# BL702 register map
Vendor: Bouffalo Lab; Series: WiFi BT; File version: 1.0
BL702 BLE + Zigbee combo chipset
Registers are 32-bit, read-write, reset 0x0 unless marked. A register's access mark holds for its fields unless they carry their own. Offsets are from the block's base; lines under a group give offsets from that group; [hi:lo] are bit positions; {n}, {i} and the like mark numbered series; 'fields as' and 'values as' point back to an identical list; <NAME> marks a mode.

## Memory map
0x40000000 GLB size 0x1000 — Global configuration register
0x40001000 RF size 0x1000 — Radio frequency control
0x40002000 GPIP size 0x1000 — Generic DAC and ADC interface control
0x40003000 sec_dbg size 0x1000
0x40004000 sec_eng size 0x1000
0x40005000 tzc_sec size 0x1000
0x40006000 tzc_nsec size 0x1000
0x40007000 ef_data_0 size 0x1000
0x40007000 ef_data_1 size 0x1000
0x40007000 ef_ctrl size 0x1000 — eFuse memory control
0x40007000 DMA size 0x1000 — Direct Memory Access module
0x40008000 cci size 0x1000
0x40009000 l1c size 0x1000 — L1 Cache control
0x4000A000 UART size 0x1000 — Universal Asynchronous Receiver Transmitter
0x4000A200 SPI size 0x1000 — Serial Peripheral Interface
0x4000A300 I2C size 0x1000 — Inter-Integrated Circuit bus
0x4000A400 PWM size 0x1000 — Pulse-Width Modulation module
0x4000A500 timer size 0x1000
0x4000A600 IR size 0x1000 — Infrared transceiver module
0x4000A700 CRC size 0x1000 — Checksum peripheral
0x4000A800 qdec size 0x1000 — Quadrature decoder control
0x4000AA00 I2S size 0x1000 — Inter-IC Sound controller
0x4000AB00 kys size 0x1000 — Key Scan
0x4000AD00 cam size 0x1000 — Camera
0x4000AE00 mjpeg size 0x1000
0x4000B000 FLASH size 0x1000 — Quad Serial Flash control
0x4000D000 emac size 0x1000 — Ethernet MAC
0x4000D800 USB size 0x1000 — Universal Serial Bus host
0x4000E000 PDS size 0x1000 — Power-Down Sleep control
0x4000F000 HBN size 0x1000 — Hibernate (Deep sleep) control
0x4000F000 AON size 0x1000

## GPIP — Generic DAC and ADC interface control
Base 0x40002000
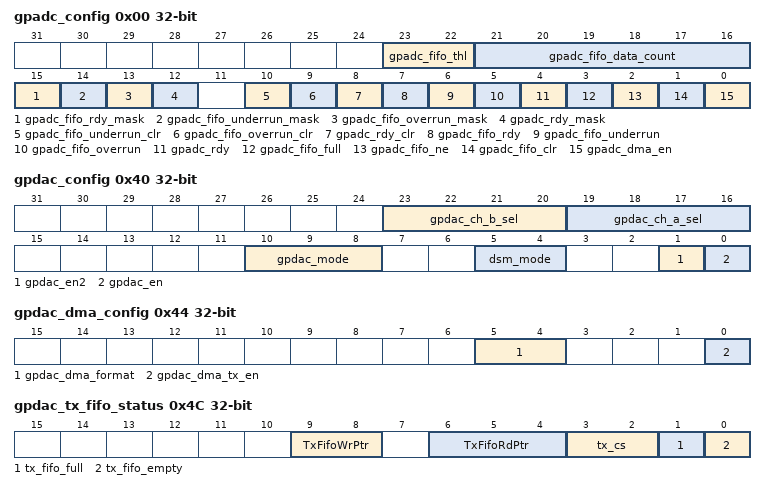
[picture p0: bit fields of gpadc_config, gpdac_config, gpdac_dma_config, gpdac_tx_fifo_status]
0x00 gpadc_config
  [23:22] gpadc_fifo_thl, [21:16] gpadc_fifo_data_count, [15] gpadc_fifo_rdy_mask, [14] gpadc_fifo_underrun_mask, [13] gpadc_fifo_overrun_mask, [12] gpadc_rdy_mask, [10] gpadc_fifo_underrun_clr, [9] gpadc_fifo_overrun_clr, [8] gpadc_rdy_clr, [7] gpadc_fifo_rdy, [6] gpadc_fifo_underrun, [5] gpadc_fifo_overrun, [4] gpadc_rdy, [3] gpadc_fifo_full, [2] gpadc_fifo_ne, [1] gpadc_fifo_clr, [0] gpadc_dma_en
0x04 gpadc_dma_rdata
  [25:0] gpadc_dma_rdata
0x40 gpdac_config
  [23:20] gpdac_ch_b_sel, [19:16] gpdac_ch_a_sel, [10:8] gpdac_mode, [5:4] dsm_mode, [1] gpdac_en2, [0] gpdac_en
0x44 gpdac_dma_config
  [5:4] gpdac_dma_format, [0] gpdac_dma_tx_en
0x48 gpdac_dma_wdata
0x4C gpdac_tx_fifo_status
  [9:8] TxFifoWrPtr, [6:4] TxFifoRdPtr, [3:2] tx_cs, [1] tx_fifo_full, [0] tx_fifo_empty

## sec_dbg
Base 0x40003000
0x00 sd_chip_id_low
0x04 sd_chip_id_high
0x08 sd_wifi_mac_low
0x0C sd_wifi_mac_high
0x10 sd_dbg_pwd_low
0x14 sd_dbg_pwd_high
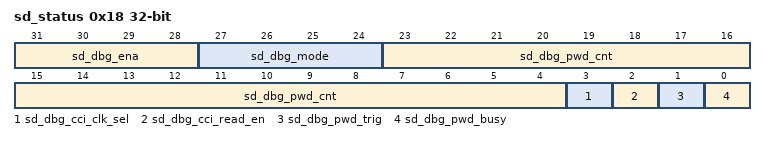
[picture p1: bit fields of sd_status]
0x18 sd_status
  [31:28] sd_dbg_ena, [27:24] sd_dbg_mode, [23:4] sd_dbg_pwd_cnt, [3] sd_dbg_cci_clk_sel, [2] sd_dbg_cci_read_en, [1] sd_dbg_pwd_trig, [0] sd_dbg_pwd_busy
0x1C sd_dbg_reserved

## tzc_sec
Base 0x40005000
Same registers: tzc_nsec 0x40006000
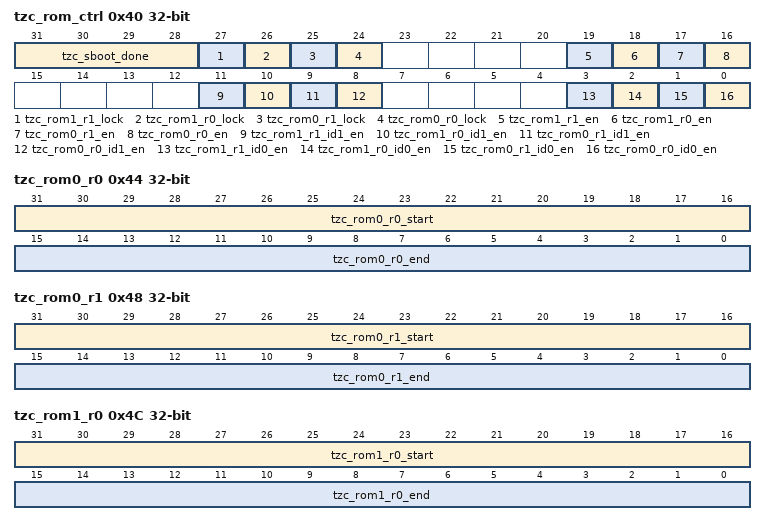
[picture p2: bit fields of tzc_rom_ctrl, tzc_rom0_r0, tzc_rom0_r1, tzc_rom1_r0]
0x40 tzc_rom_ctrl
  [31:28] tzc_sboot_done, [27] tzc_rom1_r1_lock, [26] tzc_rom1_r0_lock, [25] tzc_rom0_r1_lock, [24] tzc_rom0_r0_lock, [19] tzc_rom1_r1_en, [18] tzc_rom1_r0_en, [17] tzc_rom0_r1_en, [16] tzc_rom0_r0_en, [11] tzc_rom1_r1_id1_en, [10] tzc_rom1_r0_id1_en, [9] tzc_rom0_r1_id1_en, [8] tzc_rom0_r0_id1_en, [3] tzc_rom1_r1_id0_en, [2] tzc_rom1_r0_id0_en, [1] tzc_rom0_r1_id0_en, [0] tzc_rom0_r0_id0_en
0x44 tzc_rom0_r0
  [31:16] tzc_rom0_r0_start, [15:0] tzc_rom0_r0_end
0x48 tzc_rom0_r1
  [31:16] tzc_rom0_r1_start, [15:0] tzc_rom0_r1_end
0x4C tzc_rom1_r0
  [31:16] tzc_rom1_r0_start, [15:0] tzc_rom1_r0_end
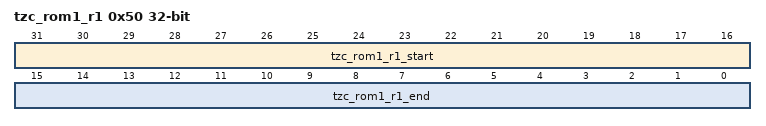
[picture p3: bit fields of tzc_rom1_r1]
0x50 tzc_rom1_r1
  [31:16] tzc_rom1_r1_start, [15:0] tzc_rom1_r1_end

## ef_data_0
Base 0x40007000
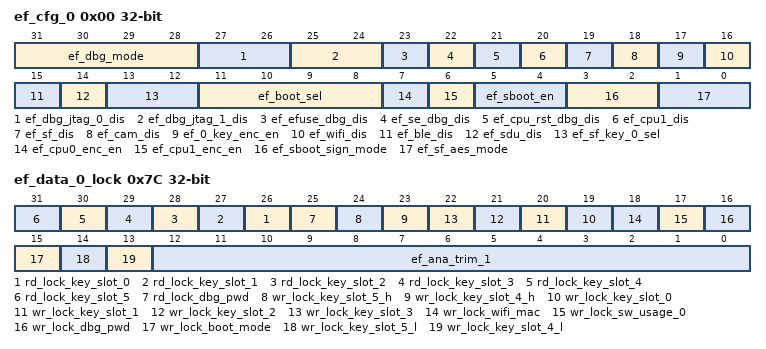
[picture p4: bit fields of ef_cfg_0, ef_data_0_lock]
0x00 ef_cfg_0
  [31:28] ef_dbg_mode, [27:26] ef_dbg_jtag_0_dis, [25:24] ef_dbg_jtag_1_dis, [23] ef_efuse_dbg_dis, [22] ef_se_dbg_dis, [21] ef_cpu_rst_dbg_dis, [20] ef_cpu1_dis, [19] ef_sf_dis, [18] ef_cam_dis, [17] ef_0_key_enc_en, [16] ef_wifi_dis, [15] ef_ble_dis, [14] ef_sdu_dis, [13:12] ef_sf_key_0_sel, [11:8] ef_boot_sel, [7] ef_cpu0_enc_en, [6] ef_cpu1_enc_en, [5:4] ef_sboot_en, [3:2] ef_sboot_sign_mode, [1:0] ef_sf_aes_mode
0x04 ef_dbg_pwd_low
0x08 ef_dbg_pwd_high
0x0C ef_ana_trim_0
0x10 ef_sw_usage_0
0x14 ef_wifi_mac_low
0x18 ef_wifi_mac_high
{0x1C+0x10*i} ef_key_slot_{i}_w0 (i=0..5)
{0x20+0x10*i} ef_key_slot_{i}_w1 (i=0..5)
{0x24+0x10*i} ef_key_slot_{i}_w2 (i=0..5)
{0x28+0x10*i} ef_key_slot_{i}_w3 (i=0..5)
0x7C ef_data_0_lock
  [n+26] rd_lock_key_slot_{n} (n=0..5), [25] rd_lock_dbg_pwd, [24] wr_lock_key_slot_5_h, [23] wr_lock_key_slot_4_h, [n+19] wr_lock_key_slot_{n} (n=0..3), [18] wr_lock_wifi_mac, [17] wr_lock_sw_usage_0, [16] wr_lock_dbg_pwd, [15] wr_lock_boot_mode, [14] wr_lock_key_slot_5_l, [13] wr_lock_key_slot_4_l, [12:0] ef_ana_trim_1
